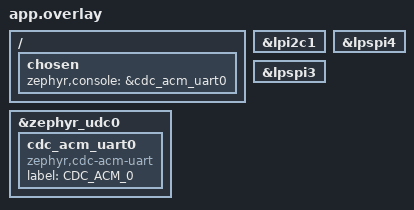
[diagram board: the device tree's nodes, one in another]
/ {
	chosen {
		zephyr,console = &cdc_acm_uart0;
	};
};

&zephyr_udc0 {
	cdc_acm_uart0: cdc_acm_uart0 {
		compatible = "zephyr,cdc-acm-uart";
		label = "CDC_ACM_0";
	};
};

&lpi2c1 {
	status = "okay";
};

&lpspi4 {
	status = "okay";
};

&lpspi3 {
	status = "okay";
};
